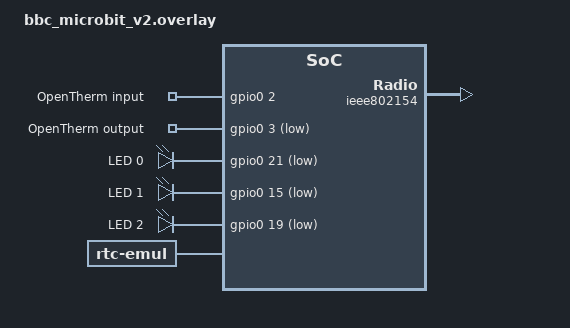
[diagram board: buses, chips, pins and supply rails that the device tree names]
// To get started, press Ctrl+Space to bring up the completion menu and view the available nodes.

// You can also use the buttons in the sidebar to perform actions on nodes.
// Actions currently available include:

// * Enabling / disabling the node
// * Adding the bus to a bus
// * Removing the node
// * Connecting ADC channels

// For more help, browse the DeviceTree documentation at https://docs.zephyrproject.org/latest/guides/dts/index.html
// You can also visit the nRF DeviceTree extension documentation at https://nrfconnect.github.io/vscode-nrf-connect/devicetree/nrfdevicetree.html

/ {
  gpio_keys {
      compatible = "gpio-keys";
      status = "okay";
      opentherm_in: opentherm_in {
          gpios = <&gpio0 2 GPIO_ACTIVE_HIGH>;
          label = "OpenTherm input";
      };
      opentherm_out: opentherm_out {
        gpios = <&gpio0 3 GPIO_ACTIVE_LOW>;
        label = "OpenTherm output";
    };
  };

  leds {
    compatible = "gpio-leds";
    led0: led_0  {
      gpios = <&gpio0 21 GPIO_ACTIVE_LOW>;
      label = "LED 0";
    };
		led1: led_1 {
			gpios = <&gpio0 15 GPIO_ACTIVE_LOW>;
			label = "LED 1";
		};
		led2: led_2 {
			gpios = <&gpio0 19 GPIO_ACTIVE_LOW>;
			label = "LED 2";
		};
	};

  rtc: rtc-emul {
		compatible = "zephyr,rtc-emul";
	};

  aliases {
    otin = &opentherm_in;
    otout = &opentherm_out;
		led0 = &led0;
		led1 = &led1;
		led2 = &led2;
    rtc = &rtc;
  };

  chosen {
    zephyr,ieee802154 = &ieee802154;
  };
};

&ieee802154 {
	status = "okay";
};

&gpio0 {
  status="okay";
  label="GPIO_0";
};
